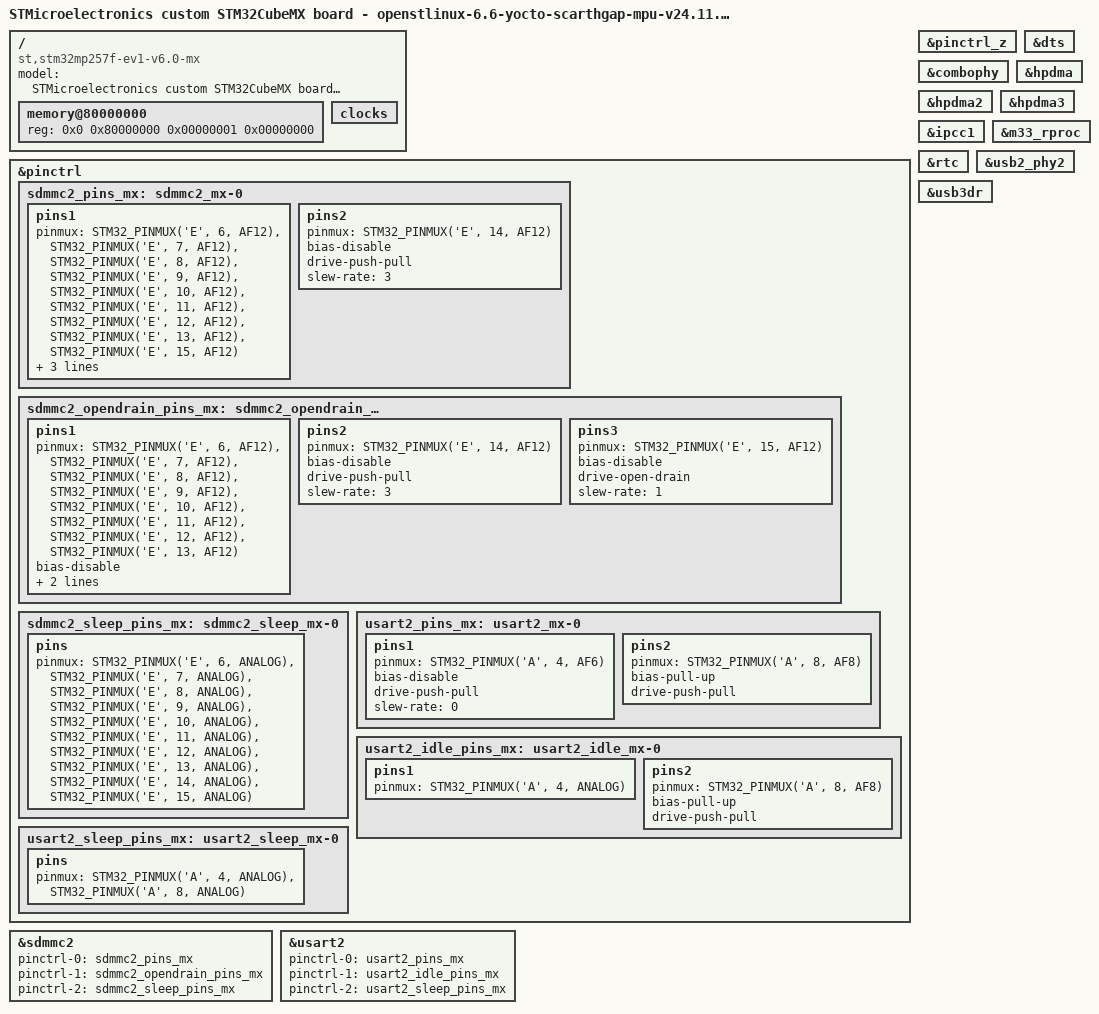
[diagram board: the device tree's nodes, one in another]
// SPDX-License-Identifier: (GPL-2.0-or-later OR BSD-3-Clause)
/*
 * Copyright (C) 2024, STMicroelectronics - All Rights Reserved
 * Author: STM32CubeMX code generation for STMicroelectronics.
 */

/* For more information on Device Tree configuration, please refer to
 * https://wiki.st.com/stm32mpu/wiki/Category:Device_tree_configuration
 */

/dts-v1/;

#include <dt-bindings/pinctrl/stm32-pinfunc.h>
#include "stm32mp257.dtsi"
#include "stm32mp25xf.dtsi"
#include "stm32mp257f-ev1-v6.0-mx-resmem.dtsi"
#include "stm32mp25xxai-pinctrl.dtsi"

/* USER CODE BEGIN includes */
/* USER CODE END includes */

/ {
	model = "STMicroelectronics custom STM32CubeMX board - openstlinux-6.6-yocto-scarthgap-mpu-v24.11.06";
	compatible = "st,stm32mp257f-ev1-v6.0-mx", "st,stm32mp257";

	memory@80000000 {
		device_type = "memory";
		reg = <0x0 0x80000000 0x00000001 0x00000000>;

		/* USER CODE BEGIN memory */
		/* USER CODE END memory */
	};

	/* USER CODE BEGIN root */
	/* USER CODE END root */

	clocks{

		/* USER CODE BEGIN clocks */
		/* USER CODE END clocks */
	};

}; /*root*/

&pinctrl {

	sdmmc2_pins_mx: sdmmc2_mx-0 {
		pins1 {
			pinmux = <STM32_PINMUX('E', 6, AF12)>, /* SDMMC2_D6 */
					 <STM32_PINMUX('E', 7, AF12)>, /* SDMMC2_D7 */
					 <STM32_PINMUX('E', 8, AF12)>, /* SDMMC2_D2 */
					 <STM32_PINMUX('E', 9, AF12)>, /* SDMMC2_D5 */
					 <STM32_PINMUX('E', 10, AF12)>, /* SDMMC2_D4 */
					 <STM32_PINMUX('E', 11, AF12)>, /* SDMMC2_D1 */
					 <STM32_PINMUX('E', 12, AF12)>, /* SDMMC2_D3 */
					 <STM32_PINMUX('E', 13, AF12)>, /* SDMMC2_D0 */
					 <STM32_PINMUX('E', 15, AF12)>; /* SDMMC2_CMD */
			bias-disable;
			drive-push-pull;
			slew-rate = <1>;
		};
		pins2 {
			pinmux = <STM32_PINMUX('E', 14, AF12)>; /* SDMMC2_CK */
			bias-disable;
			drive-push-pull;
			slew-rate = <3>;
		};
	};

	sdmmc2_opendrain_pins_mx: sdmmc2_opendrain_mx-0 {
		pins1 {
			pinmux = <STM32_PINMUX('E', 6, AF12)>, /* SDMMC2_D6 */
					 <STM32_PINMUX('E', 7, AF12)>, /* SDMMC2_D7 */
					 <STM32_PINMUX('E', 8, AF12)>, /* SDMMC2_D2 */
					 <STM32_PINMUX('E', 9, AF12)>, /* SDMMC2_D5 */
					 <STM32_PINMUX('E', 10, AF12)>, /* SDMMC2_D4 */
					 <STM32_PINMUX('E', 11, AF12)>, /* SDMMC2_D1 */
					 <STM32_PINMUX('E', 12, AF12)>, /* SDMMC2_D3 */
					 <STM32_PINMUX('E', 13, AF12)>; /* SDMMC2_D0 */
			bias-disable;
			drive-push-pull;
			slew-rate = <1>;
		};
		pins2 {
			pinmux = <STM32_PINMUX('E', 14, AF12)>; /* SDMMC2_CK */
			bias-disable;
			drive-push-pull;
			slew-rate = <3>;
		};
		pins3 {
			pinmux = <STM32_PINMUX('E', 15, AF12)>; /* SDMMC2_CMD */
			bias-disable;
			drive-open-drain;
			slew-rate = <1>;
		};
	};

	sdmmc2_sleep_pins_mx: sdmmc2_sleep_mx-0 {
		pins {
			pinmux = <STM32_PINMUX('E', 6, ANALOG)>, /* SDMMC2_D6 */
					 <STM32_PINMUX('E', 7, ANALOG)>, /* SDMMC2_D7 */
					 <STM32_PINMUX('E', 8, ANALOG)>, /* SDMMC2_D2 */
					 <STM32_PINMUX('E', 9, ANALOG)>, /* SDMMC2_D5 */
					 <STM32_PINMUX('E', 10, ANALOG)>, /* SDMMC2_D4 */
					 <STM32_PINMUX('E', 11, ANALOG)>, /* SDMMC2_D1 */
					 <STM32_PINMUX('E', 12, ANALOG)>, /* SDMMC2_D3 */
					 <STM32_PINMUX('E', 13, ANALOG)>, /* SDMMC2_D0 */
					 <STM32_PINMUX('E', 14, ANALOG)>, /* SDMMC2_CK */
					 <STM32_PINMUX('E', 15, ANALOG)>; /* SDMMC2_CMD */
		};
	};

	usart2_pins_mx: usart2_mx-0 {
		pins1 {
			pinmux = <STM32_PINMUX('A', 4, AF6)>; /* USART2_TX */
			bias-disable;
			drive-push-pull;
			slew-rate = <0>;
		};
		pins2 {
			pinmux = <STM32_PINMUX('A', 8, AF8)>; /* USART2_RX */
			bias-pull-up;
			drive-push-pull;
		};
	};

	usart2_idle_pins_mx: usart2_idle_mx-0 {
		pins1 {
			pinmux = <STM32_PINMUX('A', 4, ANALOG)>; /* USART2_TX */
		};
		pins2 {
			pinmux = <STM32_PINMUX('A', 8, AF8)>; /* USART2_RX */
			bias-pull-up;
			drive-push-pull;
		};
	};

	usart2_sleep_pins_mx: usart2_sleep_mx-0 {
		pins {
			pinmux = <STM32_PINMUX('A', 4, ANALOG)>, /* USART2_TX */
					 <STM32_PINMUX('A', 8, ANALOG)>; /* USART2_RX */
		};
	};

	/* USER CODE BEGIN pinctrl */
	/* USER CODE END pinctrl */
};

&pinctrl_z {

	/* USER CODE BEGIN pinctrl_z */
	/* USER CODE END pinctrl_z */
};

&combophy {
	status = "okay";

	/* USER CODE BEGIN combophy */
	/* USER CODE END combophy */
};

&dts {
	status = "okay";

	/* USER CODE BEGIN dts */
	/* USER CODE END dts */
};

&hpdma {
	status = "okay";

	/* USER CODE BEGIN hpdma */
	/* USER CODE END hpdma */
};

&hpdma2 {
	status = "okay";

	/* USER CODE BEGIN hpdma2 */
	/* USER CODE END hpdma2 */
};

&hpdma3 {
	status = "okay";

	/* USER CODE BEGIN hpdma3 */
	/* USER CODE END hpdma3 */
};

&ipcc1 {
	status = "okay";

	/* USER CODE BEGIN ipcc1 */
	/* USER CODE END ipcc1 */
};

&m33_rproc {
	status = "okay";

	/* USER CODE BEGIN m33_rproc */
	/* USER CODE END m33_rproc */
};

&rtc {
	status = "okay";

	/* USER CODE BEGIN rtc */
	/* USER CODE END rtc */
};

&sdmmc2 {
	pinctrl-names = "default", "opendrain", "sleep";
	pinctrl-0 = <&sdmmc2_pins_mx>;
	pinctrl-1 = <&sdmmc2_opendrain_pins_mx>;
	pinctrl-2 = <&sdmmc2_sleep_pins_mx>;
	status = "okay";

	/* USER CODE BEGIN sdmmc2 */
	/* USER CODE END sdmmc2 */
};

&usart2 {
	pinctrl-names = "default", "idle", "sleep";
	pinctrl-0 = <&usart2_pins_mx>;
	pinctrl-1 = <&usart2_idle_pins_mx>;
	pinctrl-2 = <&usart2_sleep_pins_mx>;
	status = "okay";

	/* USER CODE BEGIN usart2 */
	/* USER CODE END usart2 */
};

&usb2_phy2 {
	status = "okay";

	/* USER CODE BEGIN usb2_phy2 */
	/* USER CODE END usb2_phy2 */
};

&usb3dr {
	status = "okay";

	/* USER CODE BEGIN usb3dr */
	/* USER CODE END usb3dr */
};

/* USER CODE BEGIN addons */
#include "stm32mp257f-ev1-v6.0-mx-usercodes.dtsi"
/* USER CODE END addons */

